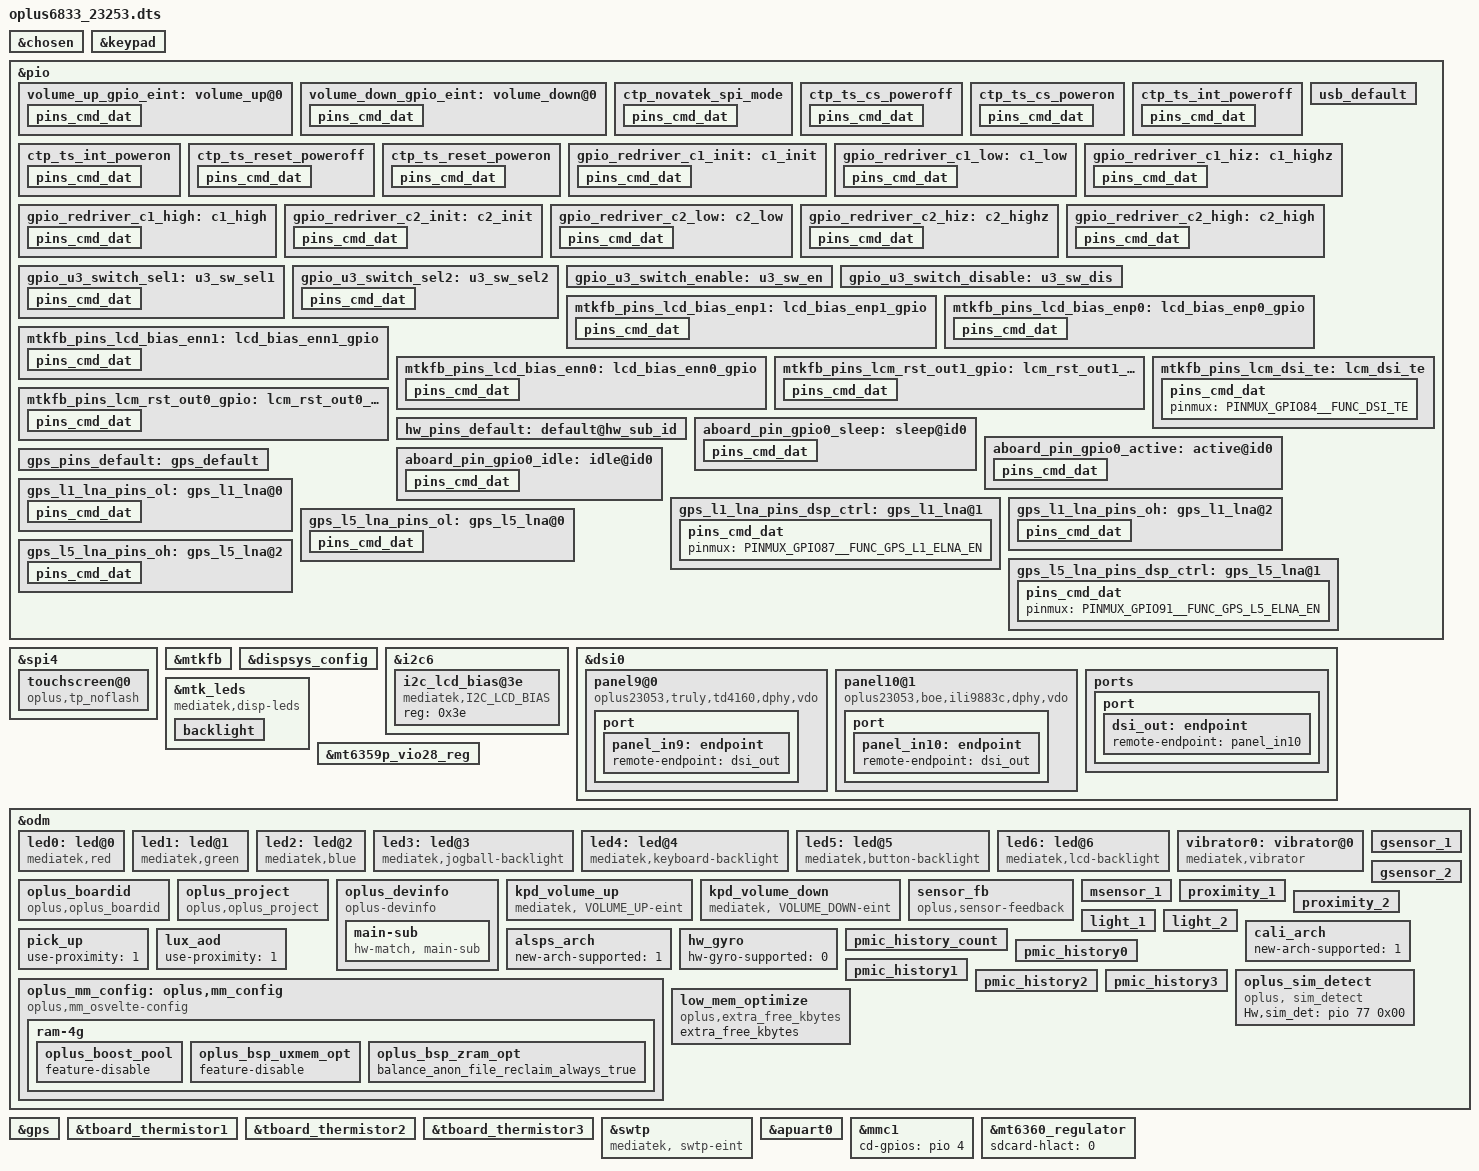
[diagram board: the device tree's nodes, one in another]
/*
 * Mediatek's mt6833 SoC device tree source
 *
 * Copyright (C) 2016 MediaTek Inc.
 *
 * This program is free software; you can redistribute it and/or modify
 * it under the terms of the GNU General Public License version 2 as
 * published by the Free Software Foundation.
 *
 * This program is distributed in the hope that it will be useful,
 * but WITHOUT ANY WARRANTY; without even the implied warranty of
 * MERCHANTABILITY or FITNESS FOR A PARTICULAR PURPOSE.
 * See http://www.gnu.org/licenses/gpl-2.0.html for more details.
 */
/dts-v1/;
/plugin/;
#include "k6833v1_64.dts"
//#ifdef OPLUS_FEATURE_NFC_BRINGUP
//#include "mediatek/nfc/mt6833_lijing_pn557.dtsi"
//#endif OPLUS_FEATURE_NFC_BRINGUP

#include "mediatek/oplus_uff_23053.dtsi"

/* chosen */
&chosen {
	atag,videolfb-fb_base_l = <0x7e605000>;
	atag,videolfb-fb_base_h = <0x0>;
	atag,videolfb-islcmfound = <1>;
	atag,videolfb-islcm_inited = <0>;
	atag,videolfb-fps= <6000>;
	atag,videolfb-vramSize= <0x1be0000>;
	atag,videolfb-lcmname=
		"nt35595_fhd_dsi_cmd_truly_nt50358_drv";
};



&keypad {
	keypad,volume-up	= <&pio 1 0x00>;
	keypad,volume-down	= <&pio 80 0x00>;
	pinctrl-names = "volume_up_as_int", "volume_down_as_int";
	pinctrl-0 = <&volume_up_gpio_eint>;
	pinctrl-1 = <&volume_down_gpio_eint>;
	status = "okay";
};
&pio {
	volume_up_gpio_eint:volume_up@0{
		pins_cmd_dat {
			pinmux = <PINMUX_GPIO1__FUNC_GPIO1>;
			slew-rate = <0>;  /*direction 0:in, 1:out*/
			input-enable;
		};
	};

	volume_down_gpio_eint:volume_down@0{
		pins_cmd_dat {
			pinmux = <PINMUX_GPIO80__FUNC_GPIO80>;
			slew-rate = <0>;  /*direction 0:in, 1:out*/
			input-enable;
		};
	};
};
#include "lijingA-23053-ilitek7807s_hlt-tp.dtsi"
//#include "lijingA-23053-ilitek7807s_boe-tp.dtsi"
#include "lijingA-23053-td4160_truly-tp.dtsi"
/* touch bringup */
&spi4 {
	status = "okay";
	#address-cells = <1>;
	#size-cells = <0>;

	touchscreen@0 {
		compatible = "oplus,tp_noflash";
		reg = <0>;
		chip-num = <2>;
		chip-name = "NF_9883C","TD4160";
		status = "okay";

		spi-max-frequency = <9600000>;	//4800000,9600000,15000000,19200000
		interrupt-parent = <&pio>;
		interrupts = <14 IRQ_TYPE_EDGE_FALLING 14 0>;
		irq-gpio = <&pio 14 0x2002>;
		reset-gpio = <&pio 15 0>;

		/*driver match info*/
		panel_type = <3 2>; /*type:2 truly  type:3 BOE*/
		firmware_name = "0xAC034BI","0xAC150TT";
		project_id = <23253>;
                touchpanel,tp-index = <0>;
		platform_support_project = <23053 23054 23055 23253>;
		platform_support_project_dir = <23053 23053 23053 23053>;
		platform_support_project_commandline = "oplus23053_ili9883c_boe_hd_dsi_vdo_lcm_drv","oplus23053_td4160_truly_hd_dsi_vdo_lcm_drv";

		touchpanel,smooth-level = <255 5 4 3 2 1>;
 		touchpanel,sensitive-level = <255 1 2 3 4 5>;

		/*panel properities*/
		touchpanel,max-num-support = <10>;
		touchpanel,tx-rx-num = <18 32>;
		touchpanel,panel-coords = <720 1612>;
		touchpanel,display-coords = <720 1612>;
		touchpanel,touchmajor-limit = <0 54>;

		/*tp-pinctrl*/
		pinctrl-names = "default","pin_set_low", "pin_set_high";
		pinctrl-0 = <&ctp_novatek_spi_mode>;
		pinctrl-1 = <&ctp_ts_cs_poweroff &ctp_ts_int_poweroff &ctp_ts_reset_poweroff>;
		pinctrl-2 = <&ctp_ts_cs_poweron  &ctp_ts_int_poweron  &ctp_ts_reset_poweron>;

		/*sw-feature*/
		incell_screen;
		irq_need_dev_resume_ok;
		fw_edge_limit_support;
		black_gesture_support;
		charger_pump_support;
		//headset_pump_support;
		esd_handle_support;
		black_gesture_test_support;
		game_switch_support;
		noflash_support;
		lcd_trigger_load_tp_fw_support;
		smart_gesture_support;
		pressure_report_support;
		fw_update_app_support;
		health_monitor_v2_support;
                exception_upload_support;
		fw_update_in_probe_with_headfile;
		touchpanel,button-type = <4>;
		suspend_gesture_cfg;
	};
};

&pio {
	ctp_novatek_spi_mode:ctp_novatek_spi_mode{
		pins_cmd_dat {
			pinmux = <PINMUX_GPIO12__FUNC_SPI4_MI>,
				<PINMUX_GPIO13__FUNC_SPI4_MO>,
				<PINMUX_GPIO97__FUNC_SPI4_CLK>,
				<PINMUX_GPIO98__FUNC_SPI4_CSB>;
			drive-strength = <4>;
		};
	};
	ctp_ts_cs_poweroff: ctp_ts_cs_poweroff {
		pins_cmd_dat {
			pinmux = <PINMUX_GPIO98__FUNC_GPIO98>;
			slew-rate = <1>;
			output-low;
			bias-disable;
			//drive-strength = <4>;
		};
	};
	ctp_ts_cs_poweron: ctp_ts_cs_poweron {
		pins_cmd_dat {
			pinmux = <PINMUX_GPIO98__FUNC_SPI4_CSB>;
			drive-strength = <4>;
			//output-high;
		};
	};
	ctp_ts_int_poweroff: ctp_ts_int_poweroff {
		pins_cmd_dat {
			pinmux = <PINMUX_GPIO14__FUNC_GPIO14>;
			slew-rate = <1>;
			output-low;
			bias-disable;
		};
	};
	ctp_ts_int_poweron: ctp_ts_int_poweron {
		pins_cmd_dat {
			pinmux = <PINMUX_GPIO14__FUNC_GPIO14>;
			slew-rate = <0>;
			input-enable;
			bias-pull-up = <00>;
		};
	};
	ctp_ts_reset_poweroff: ctp_ts_reset_poweroff {
		pins_cmd_dat {
			pinmux = <PINMUX_GPIO15__FUNC_GPIO15>;
			slew-rate = <1>;
			output-low;
			bias-disable;
		};
	};

	ctp_ts_reset_poweron: ctp_ts_reset_poweron {
		pins_cmd_dat {
			pinmux = <PINMUX_GPIO15__FUNC_GPIO15>;
			slew-rate = <1>;
			output-high;
			bias-disable;
		};
	};
};
/* touch bringup */

/* USB SWITCH GPIO start */
&pio {
	usb_default: usb_default {
	};

	gpio_redriver_c1_init: c1_init {
		pins_cmd_dat {
			pinmux = <PINMUX_GPIO41__FUNC_GPIO41>;
			slew-rate = <1>;
			output-low;
		};
	};

	gpio_redriver_c1_low: c1_low {
		pins_cmd_dat {
			pinmux = <PINMUX_GPIO41__FUNC_GPIO41>;
			slew-rate = <1>;
			output-low;
		};
	};

	gpio_redriver_c1_hiz: c1_highz {
		pins_cmd_dat {
			pinmux = <PINMUX_GPIO41__FUNC_GPIO41>;
			slew-rate= <0>;
			bias-disable;
		};
	};

	gpio_redriver_c1_high: c1_high {
		pins_cmd_dat {
			pinmux = <PINMUX_GPIO41__FUNC_GPIO41>;
			slew-rate = <1>;
			output-high;
		};
	};

	gpio_redriver_c2_init: c2_init {
		pins_cmd_dat {
			pinmux = <PINMUX_GPIO40__FUNC_GPIO40>;
			slew-rate = <1>;
			output-low;
		};
	};

	gpio_redriver_c2_low: c2_low {
		pins_cmd_dat {
			pinmux = <PINMUX_GPIO40__FUNC_GPIO40>;
			slew-rate = <1>;
			output-low;
		};
	};

	gpio_redriver_c2_hiz: c2_highz {
		pins_cmd_dat {
			pinmux = <PINMUX_GPIO40__FUNC_GPIO40>;
			slew-rate= <0>;
			bias-disable;
		};
	};

	gpio_redriver_c2_high: c2_high {
		pins_cmd_dat {
			pinmux = <PINMUX_GPIO40__FUNC_GPIO40>;
			slew-rate = <1>;
			output-high;
		};
	};

	gpio_u3_switch_sel1: u3_sw_sel1 {
		pins_cmd_dat {
			pinmux = <PINMUX_GPIO11__FUNC_GPIO11>;
			slew-rate = <1>;
			output-low;
		};
	};

	gpio_u3_switch_sel2: u3_sw_sel2 {
		pins_cmd_dat {
			pinmux = <PINMUX_GPIO11__FUNC_GPIO11>;
			slew-rate = <1>;
			output-high;
		};
	};

	gpio_u3_switch_enable: u3_sw_en {
	};

	gpio_u3_switch_disable: u3_sw_dis {
	};
};

#ifndef CONFIG_FPGA_EARLY_PORTING
&pio {
	mtkfb_pins_lcd_bias_enp1: lcd_bias_enp1_gpio {
		pins_cmd_dat {
			pinmux = <PINMUX_GPIO137__FUNC_GPIO137>;
			slew-rate = <1>;
			output-high;
		};
	};

	mtkfb_pins_lcd_bias_enp0: lcd_bias_enp0_gpio {
		pins_cmd_dat {
			pinmux = <PINMUX_GPIO137__FUNC_GPIO137>;
			slew-rate = <1>;
			output-low;
		};
	};

	mtkfb_pins_lcd_bias_enn1: lcd_bias_enn1_gpio {
		pins_cmd_dat {
			pinmux = <PINMUX_GPIO138__FUNC_GPIO138>;
			slew-rate = <1>;
			output-high;
		};
	};

	mtkfb_pins_lcd_bias_enn0: lcd_bias_enn0_gpio {
		pins_cmd_dat {
			pinmux = <PINMUX_GPIO138__FUNC_GPIO138>;
			slew-rate = <1>;
			output-low;
		};
	};

	mtkfb_pins_lcm_rst_out1_gpio: lcm_rst_out1_gpio {
		pins_cmd_dat {
			pinmux = <PINMUX_GPIO86__FUNC_GPIO86>;
			slew-rate = <1>;
			output-high;
		};
	};

	mtkfb_pins_lcm_rst_out0_gpio: lcm_rst_out0_gpio {
		pins_cmd_dat {
			pinmux = <PINMUX_GPIO86__FUNC_GPIO86>;
			slew-rate = <1>;
			output-low;
		};
	};
	mtkfb_pins_lcm_dsi_te: lcm_dsi_te {
		pins_cmd_dat {
			pinmux = <PINMUX_GPIO84__FUNC_DSI_TE>;
		};
	};
};

&mtkfb {
	pinctrl-names = "lcd_bias_enp1_gpio", "lcd_bias_enp0_gpio",
		"lcd_bias_enn1_gpio", "lcd_bias_enn0_gpio",
		"lcm_rst_out1_gpio", "lcm_rst_out0_gpio",
		"mode_te_te";
	pinctrl-0 = <&mtkfb_pins_lcd_bias_enp1>;
	pinctrl-1 = <&mtkfb_pins_lcd_bias_enp0>;
	pinctrl-2 = <&mtkfb_pins_lcd_bias_enn1>;
	pinctrl-3 = <&mtkfb_pins_lcd_bias_enn0>;
	pinctrl-4 = <&mtkfb_pins_lcm_rst_out1_gpio>;
	pinctrl-5 = <&mtkfb_pins_lcm_rst_out0_gpio>;
	pinctrl-6 = <&mtkfb_pins_lcm_dsi_te>;
	status = "okay";
};
&dispsys_config {
	pinctrl-names =
		"lcm_rst_out1_gpio", "lcm_rst_out0_gpio",
		"mode_te_te";
	pinctrl-0 = <&mtkfb_pins_lcm_rst_out1_gpio>;
	pinctrl-1 = <&mtkfb_pins_lcm_rst_out0_gpio>;
	pinctrl-2 = <&mtkfb_pins_lcm_dsi_te>;
	status = "okay";

	helper-value = <0>, /*MTK_DRM_OPT_STAGE*/
		<1>, /*MTK_DRM_OPT_USE_CMDQ*/
		<1>, /*MTK_DRM_OPT_USE_M4U*/
		<1>, /*MTK_DRM_OPT_MMQOS_SUPPORT*/
		<1>, /*MTK_DRM_OPT_MMDVFS_SUPPORT*/
		<0>, /*MTK_DRM_OPT_SODI_SUPPORT*/
		<1>, /*MTK_DRM_OPT_IDLE_MGR*/
		<0>, /*MTK_DRM_OPT_IDLEMGR_SWTCH_DECOUPLE*/
		<0>, /*MTK_DRM_OPT_IDLEMGR_BY_REPAINT*/
		<0>, /*MTK_DRM_OPT_IDLEMGR_ENTER_ULPS*/
		<0>, /*MTK_DRM_OPT_IDLEMGR_KEEP_LP11*/
		<0>, /*MTK_DRM_OPT_DYNAMIC_RDMA_GOLDEN_SETTING*/
		<1>, /*MTK_DRM_OPT_IDLEMGR_DISABLE_ROUTINE_IRQ*/
		<0>, /*MTK_DRM_OPT_MET_LOG*/
		<1>, /*MTK_DRM_OPT_USE_PQ*/
		<1>, /*MTK_DRM_OPT_ESD_CHECK_RECOVERY*/
		<0>, /*MTK_DRM_OPT_ESD_CHECK_SWITCH*/
		<1>, /*MTK_DRM_OPT_PRESENT_FENCE*/
		<0>, /*MTK_DRM_OPT_RDMA_UNDERFLOW_AEE*/
		<1>, /*MTK_DRM_OPT_DSI_UNDERRUN_AEE*/
		<1>, /*MTK_DRM_OPT_HRT*/
		<1>, /*MTK_DRM_OPT_HRT_MODE*/
		<0>, /*MTK_DRM_OPT_DELAYED_TRIGGER*/
		<1>, /*MTK_DRM_OPT_OVL_EXT_LAYER*/
		<0>, /*MTK_DRM_OPT_AOD*/
		<1>, /*MTK_DRM_OPT_RPO*/
		<0>, /*MTK_DRM_OPT_DUAL_PIPE*/
		<0>, /*MTK_DRM_OPT_DC_BY_HRT*/
		<0>, /*MTK_DRM_OPT_OVL_WCG*/
		<0>, /*MTK_DRM_OPT_OVL_SBCH*/
		<1>, /*MTK_DRM_OPT_COMMIT_NO_WAIT_VBLANK*/
		<0>, /*MTK_DRM_OPT_MET*/
		<0>, /*MTK_DRM_OPT_REG_PARSER_RAW_DUMP*/
		<0>, /*MTK_DRM_OPT_VP_PQ*/
		<0>, /*MTK_DRM_OPT_GAME_PQ*/
		<0>, /*MTK_DRM_OPT_MMPATH*/
		<0>, /*MTK_DRM_OPT_HBM*/
		<1>, /*MTK_DRM_OPT_VDS_PATH_SWITCH*/
		<0>, /*MTK_DRM_OPT_LAYER_REC*/
		<1>, /*MTK_DRM_OPT_CLEAR_LAYER*/
		<0>, /*MTK_DRM_OPT_LFR*/
		<0>, /*MTK_DRM_OPT_SF_PF*/
		<0>, /*MTK_DRM_OPT_DYN_MIPI_CHANGE*/
		<0>, /*MTK_DRM_OPT_PRIM_DUAL_PIPE*/
		<0>, /*MTK_DRM_OPT_MSYNC2_0*/
		<1>, /*MTK_DRM_OPT_VIRTUAL_DISP*/
		<0>, /*MTK_DRM_OPT_MML_PRIMARY*/
		<0>, /*MTK_DRM_OPT_DUAL_TE*/
		<0>, /*MTK_DRM_OPT_RES_SWITCH*/
		<0>, /*MTK_DRM_OPT_SHARE_SRAM*/
		<1>; /*MTK_DRM_OPT_SPHRT*/
};

/* add for dual-mic or singlemic with miso1 */
/*
&aud_dat_miso1_off {
	pins_cmd1_dat {
		pinmux = <PINMUX_GPIO160__FUNC_GPIO160>;
		input-enable;
		bias-pull-down;
	};
};
&aud_dat_miso1_on {
	pins_cmd1_dat {
		pinmux = <PINMUX_GPIO160__FUNC_AUD_DAT_MISO1>;
		input-schmitt-enable;
		bias-disable;
	};
};
*/


&i2c6 {

       i2c_lcd_bias@3e {
               compatible = "mediatek,I2C_LCD_BIAS";
               reg = <0x3e>;
               status = "okay";
       };
};

&dsi0 {
	status = "okay";
	#address-cells = <1>;
	#size-cells = <0>;
	panel9@0 {
		compatible = "oplus23053,truly,td4160,dphy,vdo";
		reg = <0>;
		reset-gpios = <&pio 86 0>;
		ldo-gpios = <&pio 41 0>;
		bias-gpios = <&pio 137 0>,
				<&pio 138 0>;
		pinctrl-names = "default";
		port {
			panel_in9: endpoint {
				remote-endpoint = <&dsi_out>;
			};
		};
	};

	panel10@1 {
		compatible = "oplus23053,boe,ili9883c,dphy,vdo";
		reg = <1>;
		reset-gpios = <&pio 86 0>;
		ldo-gpios = <&pio 41 0>;
		bias-gpios = <&pio 137 0>,
			<&pio 138 0>;
		port {
			panel_in10: endpoint {
		    		remote-endpoint = <&dsi_out>;
	    		};
		};
	};
	ports {
		port {
			dsi_out: endpoint {
				remote-endpoint = <&panel_in10>;
			};
		};
	};
};
#endif

&mtk_leds {
	compatible = "mediatek,disp-leds";
        backlight {
                label = "lcd-backlight";
                max-brightness = <4095>;
		max-hw-brightness = <4095>;
                led-bits = <12>;
                trans-bits = <12>;
                default-state = "on";
                apollo-state = "disable";
        };
};


/*#ifdef OPLUS_FEATURE_TP_BASIC add for elsa/20151 audio board match in factory mode*/
&pio {
	hw_pins_default:default@hw_sub_id {
	};
	aboard_pin_gpio0_sleep:sleep@id0 {
		pins_cmd_dat {
			pinmux = <PINMUX_GPIO19__FUNC_GPIO19>;
			slew-rate = <0>;
			bias-pull-down;
			input-enable;
		};
	};

	aboard_pin_gpio0_active:active@id0 {
		pins_cmd_dat {
			pinmux = <PINMUX_GPIO19__FUNC_GPIO19>;
			slew-rate = <0>;
			bias-pull-up;
			input-enable;
		};
	};

	aboard_pin_gpio0_idle:idle@id0 {
		pins_cmd_dat {
			pinmux = <PINMUX_GPIO19__FUNC_GPIO19>;
			slew-rate = <0>;
			bias-disable;
			input-enable;
		};
	};
};
/*#endif OPLUS_FEATURE_TP_BASIC*/

&mt6359p_vio28_reg {
	regulator-name = "vio28";
	regulator-min-microvolt = <3000000>;
	regulator-max-microvolt = <3000000>;
	regulator-enable-ramp-delay = <1920>;
};

&odm {
	led0:led@0 {
		compatible = "mediatek,red";
		led_mode = <0>;
		data = <1>;
		pwm_config = <0 0 0 0 0>;
	};
	led1:led@1 {
		compatible = "mediatek,green";
		led_mode = <0>;
		data = <1>;
		pwm_config = <0 0 0 0 0>;
	};
	led2:led@2 {
		compatible = "mediatek,blue";
		led_mode = <0>;
		data = <1>;
		pwm_config = <0 0 0 0 0>;
	};
	led3:led@3 {
		compatible = "mediatek,jogball-backlight";
		led_mode = <0>;
		data = <1>;
		pwm_config = <0 0 0 0 0>;
	};
	led4:led@4 {
		compatible = "mediatek,keyboard-backlight";
		led_mode = <0>;
		data = <1>;
		pwm_config = <0 0 0 0 0>;
	};
	led5:led@5 {
		compatible = "mediatek,button-backlight";
		led_mode = <0>;
		data = <1>;
		pwm_config = <0 0 0 0 0>;
	};
	led6:led@6 {
		compatible = "mediatek,lcd-backlight";
		led_mode = <4>;
		data = <1>;
		pwm_config = <0 1 0 0 0>;
	};
	vibrator0:vibrator@0 {
		compatible = "mediatek,vibrator";
	};
	oplus_boardid:oplus_boardid {
		compatible = "oplus,oplus_boardid";
		oplus_boardid,dtsino="23253";//only one u32
		oplus_boardid,pcbmask="0xffff";//all mask 0xffff
	};
	oplus_project:oplus_project {
		compatible = "oplus,oplus_project";
	};
/*#ifdef OPLUS_FEATURE_TP_BASIC add for elsa/20151 audio board match in factory mode*/
	oplus_devinfo:oplus_devinfo {
		compatible = "oplus-devinfo";
		pinctrl-names = "default", "aboard_gpio0_sleep", "aboard_gpio0_active", "aboard_gpio0_idle";
		pinctrl-0 = <&hw_pins_default>;
		pinctrl-1 = <&aboard_pin_gpio0_sleep>;
		pinctrl-2 = <&aboard_pin_gpio0_active>;
		pinctrl-3 = <&aboard_pin_gpio0_idle>;
		main-sub {
			use_tristate_gpio;
			compatible = "hw-match, main-sub";
			aboard-gpio0 = <&pio 19 0x00>;
			aboard-patterns = <0 0 0 1>;	/*0[high-resistance] 1[pull-down] 2[pull-up]*/
			/*main board*/
			match-projects = <23053 23054 23055 23253>;
		};
	};
/*#endif OPLUS_FEATURE_TP_BASIC*/

	
/* Add volume up and down */
	kpd_volume_up:kpd_volume_up {
		compatible = "mediatek, VOLUME_UP-eint";
		interrupt-parent = <&pio>;
		interrupts = <1 IRQ_TYPE_EDGE_FALLING 1 0>;
		debounce = <32000>;
		status = "okay";
	};

	kpd_volume_down:kpd_volume_down {
		compatible = "mediatek, VOLUME_DOWN-eint";
		interrupt-parent = <&pio>;
		interrupts = <80 IRQ_TYPE_EDGE_FALLING 80 0>;
		debounce = <32000>;
		status = "okay";
	};

	sensor_fb: sensor_fb {
		compatible = "oplus,sensor-feedback";
	};

	/*
	enum {
		LIS3DH,
		LSM6DS3,
		BMI160,
		LIS2HH12,
		LSM6DSM,
		BMI2XY,
		LSM6DSO,
		ICM4X6XX,
		SC7A20,
		BMA4XY,
		BMI3XY,
		ICM4N607,
		BMA2X2,
		MC34X9,
		STK8XXX,
};
	*/

	gsensor_1: gsensor_1 {
		status = "okay";
		sensor_name = <3>;//LIS2HH12
		device_name = "LIS2HH12";
		i2c_num = <2>;
		i2c_addr = <0>;
		direction = <2>;
		eint_num = <3>;
		gyro_cali_version= <2>;
		acc_cali_range= <300 300 300>; //300mg
		stdev_xyz = <33>;
		gyro_gain =<100>;
	};
	gsensor_2: gsensor_2 {
		status = "okay";
		sensor_name = <9>;//BMA4XY
		device_name = "bma4xy";
		i2c_num = <2>;
		i2c_addr = <0>;
		direction = <9>;
		eint_num = <3>;
		gyro_cali_version= <2>;
		acc_cali_range= <300 300 300>; //300mg
		stdev_xyz = <18>;
		gyro_gain =<100>;
	};
	/*
	enum {
		AKM09911,
		MMC3530,
		MMC5603,
		MXG4300,
		QMC6308,
	};
	*/
	msensor_1: msensor_1 {
		status = "okay";
		sensor_name = <3>;//MXG4300
		i2c_num = <0>;
		i2c_addr = <12>;
		direction = <2>;
		eint_num = <0>;
		soft-mag-parameter = <10121 0 121 1 229 0 109 1 9950 0 297 0 1 1 52 1 10571 0>;
	};
	/*
	enum {
		TMD2725,
		APSD9922,
		STK3335,
		STK3331,
		STK2232,
		TCS3701,
		STK32600,
		STK33502,
		MN78911,
		TMD2755x12,
	};
	*/
	proximity_1: proximity_1 {
		status = "okay";
		sensor_name = <7>;//STK33502
		i2c_num = <0>;
		i2c_addr = <0x46>;
		direction = <4>;
		eint_num = <3>;
		low_step = <300>;
		high_step = <400>;
		low_limit = <650>;
		high_limit = <1050>;
		dirty_low_step = <200>;
		dirty_high_step = <300>;
		ps_dirty_limit = <2000>;
		ps_ir_limit = <2000>;
		ps_adjust_min = <0>;
		ps_adjust_max = <1850>;
		sampling_count = <5>;
		step_max = <400>;
		step_min = <100>;
		step_div = <2000>;
		anti_shake_delta = <70>;
		dynamic_cali_max = <5000>;
		raw2offset_radio = <1000>;
		offset_max = <60000>;
		offset_range_min = <0>;
		offset_range_max = <65534>;
		force_cali_limit = <2000>;
		cali_jitter_limit = <30>;
		cal_offset_margin = <3000>;
		sensor-reg = <0x01 0x33>;
	};
	proximity_2: proximity_2 {
		status = "okay";
		sensor_name = <12>;//SIP3515
		i2c_num = <0>;
		i2c_addr = <0x58>;
		direction = <4>;
		eint_num = <3>;
		low_step = <300>;
		high_step = <400>;
		low_limit = <200>;
		high_limit = <270>;
		dirty_low_step = <120>;
		dirty_high_step = <200>;
		ps_dirty_limit = <1800>;
		ps_ir_limit = <2000>;
		ps_adjust_min = <0>;
		ps_adjust_max = <600>;
		sampling_count = <5>;
		step_max = <400>;
		step_min = <50>;
		step_div = <2000>;
		anti_shake_delta = <50>;
		dynamic_cali_max = <2000>;
		raw2offset_radio = <1000>;
		offset_max = <60000>;
		offset_range_min = <0>;
		offset_range_max = <65534>;
		force_cali_limit = <2000>;
		cali_jitter_limit = <20>;
		cal_offset_margin = <3000>;
	};
	light_1: light_1 {
		status = "okay";
		sensor_name = <7>;//STK33502
		i2c_num = <0>;
		i2c_addr = <0x46>;
		direction = <4>;
		eint_num = <3>;
		als_buffer_length =<8>;
		als_ratio = <90>;
		als_type = <1>;//<1-normal;2-under screen;3-normal needed compensation>
		device_name = "stk33502";
		als_spectral_coefficient = <1>;
		coefficient_mode = <6>; //6x coefficient mode
		als_coef_a = <4300>; //*100
		als_coef_b = <16600>; //*100
		als_coef_c = <1550>; //*100
		als_coef_d = <4500>; //*100
		als_coef_e = <8700>; //*100
		als_coef_ratio = <70>;
	};
	light_2: light_2 {
		status = "okay";
		sensor_name = <12>;//SIP3515
		i2c_num = <0>;
		i2c_addr = <0x58>;
		direction = <4>;
		eint_num = <3>;
		als_ratio = <210>;
		als_buffer_length =<8>;
		als_type = <1>;//<1-normal;2-under screen;3-normal needed compensation>
		device_name = "sip3515";
		coefficient_mode = <6>;
		als_coef_a = <963>; //*100
		als_coef_b = <60>; //*100
		als_coef_c = <963>; //*100
		als_coef_d = <60>; //*100
		als_coef_e = <2490>; //*100
		als_coef_ratio = <1500>;
	};
	cali_arch: cali_arch {
		status = "okay";
		new-arch-supported = <1>;
	};
	pick_up: pick_up {
		status = "okay";
		use-proximity = <1>;
	};
	lux_aod: lux_aod {
		status = "okay";
		use-proximity = <1>;
	};
	alsps_arch: alsps_arch {
		status = "okay";
		new-arch-supported = <1>;
	};
	hw_gyro: hw_gyro {
		status = "okay";
		hw-gyro-supported = <0>;
	};

	pmic_history_count:pmic_history_count {
	};
	pmic_history0:pmic_history0 {
	};
	pmic_history1:pmic_history1 {
	};
	pmic_history2:pmic_history2 {
	};
	pmic_history3:pmic_history3 {
	};

//#ifdef OPLUS_FEATURE_TP_BASIC
/* Add for sim detect */
    oplus_sim_detect {
        compatible = "oplus, sim_detect";
        Hw,sim_det = <&pio 77 0x00>;
    };
//#endif /* OPLUS_FEATURE_TP_BASIC */
};

/* GPS GPIO standardization start */
&pio {
	gps_pins_default: gps_default {
	};

	gps_l1_lna_pins_ol: gps_l1_lna@0 {
		pins_cmd_dat {
			pinmux = <PINMUX_GPIO87__FUNC_GPIO87>;
			output-low;
		};
	};
	gps_l1_lna_pins_dsp_ctrl: gps_l1_lna@1 {
		pins_cmd_dat {
			pinmux = <PINMUX_GPIO87__FUNC_GPS_L1_ELNA_EN>;
		};
	};
	gps_l1_lna_pins_oh: gps_l1_lna@2 {
		pins_cmd_dat {
			pinmux = <PINMUX_GPIO87__FUNC_GPIO87>;
			output-high;
		};
	};

	gps_l5_lna_pins_ol: gps_l5_lna@0 {
		pins_cmd_dat {
			pinmux = <PINMUX_GPIO91__FUNC_GPIO91>;
			output-low;
		};
	};
	gps_l5_lna_pins_dsp_ctrl: gps_l5_lna@1 {
		pins_cmd_dat {
			pinmux = <PINMUX_GPIO91__FUNC_GPS_L5_ELNA_EN>;
		};
	};
	gps_l5_lna_pins_oh: gps_l5_lna@2 {
		pins_cmd_dat {
			pinmux = <PINMUX_GPIO91__FUNC_GPIO91>;
			output-high;
		};
	};
};

&gps {
	pinctrl-names = "default",
		"gps_l1_lna_disable",
		"gps_l1_lna_dsp_ctrl",
		"gps_l1_lna_enable",
		"gps_l5_lna_disable",
		"gps_l5_lna_dsp_ctrl",
		"gps_l5_lna_enable";
	pinctrl-0 = <&gps_pins_default>;
	pinctrl-1 = <&gps_l1_lna_pins_ol>;
	pinctrl-2 = <&gps_l1_lna_pins_dsp_ctrl>;
	pinctrl-3 = <&gps_l1_lna_pins_oh>;
	pinctrl-4 = <&gps_l5_lna_pins_ol>;
	pinctrl-5 = <&gps_l5_lna_pins_dsp_ctrl>;
	pinctrl-6 = <&gps_l5_lna_pins_oh>;
	status = "okay";
};
/* GPS GPIO standardization end */


/* FINGERPRINT end */
//#endif /*OPLUS_FEATURE_FINGERPRINT*/

/*bts*/
&tboard_thermistor1{
		 oplus,ntc_cust_support = <1>;
		 oplus,ntc_pull_up_r = <100000>;
};
/*btsmdpa*/
&tboard_thermistor2{
		 oplus,ntc_cust_support = <1>;
		 oplus,ntc_pull_up_r = <100000>;
};
/*btsnrpa*/
&tboard_thermistor3{
		 oplus,ntc_cust_support = <1>;
		 oplus,ntc_pull_up_r = <100000>;
};
//#ifdef OPLUS_VENDOR_SWTP
&swtp {
    compatible = "mediatek, swtp-eint";
};
//#endif  /*OPLUS_VENDOR_SWTP*/
//#endif /* OPLUS_FEATURE_FINGERPRINT */
#include "mediatek/cust_mt6833_camera_23253.dtsi"
#include <oplus6833_23253/cust.dtsi>
//#include "mediatek/cust_mt6833_nfc_20796.dtsi"
#include "mediatek/cust_mt6833_lijingA_audio.dtsi"
//#ifdef OPLUS_FEATURE_CHG_BASIC
/*add for charging */
#include "mediatek/oplus_charge_mt6833_23253.dtsi"
&apuart0 {
	rxpin = <61>;
	txpin = <62>;
};
//#endif

&mmc1 {
    cd-gpios = <&pio 4 0>;
    status = "okay";
};

&mt6360_regulator {
    sdcard-hlact = <0>;
};

&odm {
	oplus_mm_config: oplus,mm_config {
		compatible = "oplus,mm_osvelte-config";
		ram-4g {
			oplus_boost_pool {
				feature-disable;
			};
			oplus_bsp_uxmem_opt {
				feature-disable;
			};
			oplus_bsp_zram_opt {
				balance_anon_file_reclaim_always_true;
			};
		};
	};
};

&odm {
/* Add for low_mem_optimize */
	low_mem_optimize {
		compatible = "oplus,extra_free_kbytes";
		extra_free_kbytes;
	};
};

/*End of this file, DO NOT ADD ANYTHING HERE*/
